# max32660 register map
Vendor: Maxim Integrated; Series: ARMCM4; File version: 1.0
CPU: CM4 r2p1, little endian, MPU, FPU, 3 interrupt priority bits
Registers are 32-bit, read-write, reset 0x0 unless marked. A register's access mark holds for its fields unless they carry their own. Offsets are from the block's base; [hi:lo] are bit positions; {n}, {i} and the like mark numbered series.

## ICC0 — Instruction Cache Controller Registers
Base 0x4002A000
Same registers: ICC1 0x4002F000
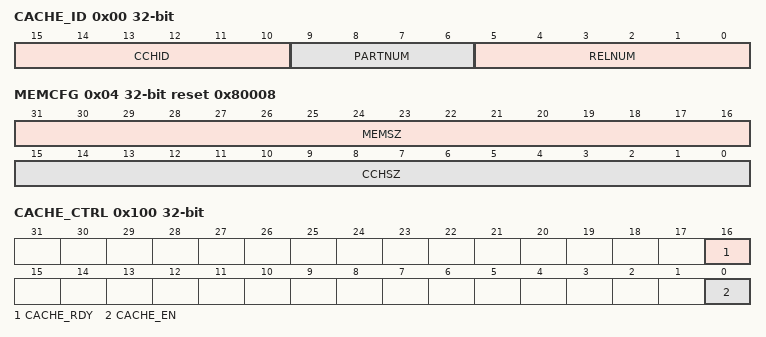
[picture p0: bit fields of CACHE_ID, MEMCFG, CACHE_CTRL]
0x00 CACHE_ID ro
  [15:10] CCHID — Cache ID. This field reflects the value of the C_ID_CACHEID configuration parameter.
  [9:6] PARTNUM — Part Number. This field reflects the value of C_ID_PART_NUMBER configuration parameter.
  [5:0] RELNUM — Release Number. Identifies the RTL release version.
0x04 MEMCFG ro reset 0x80008 — Memory Configuration Register.
  [31:16] MEMSZ — Main Memory Size. Indicates the total size, in units of 128 Kbytes, of code memory accessible to the cache controller.
  [15:0] CCHSZ — Cache Size. Indicates total size in Kbytes of cache.
0x100 CACHE_CTRL — Cache Control and Status Register.
  [16] CACHE_RDY ro — Cache Ready flag. Cleared by hardware when at any time the cache as a whole is invalidated (including a system reset). When this bit is 0, the cache is effectively in bypass mode (instruction fetches will come from main memory or from the line fill buffer). Set by hardware when the invalidate operation is complete and the cache is ready.
    0=notReady; 1=ready
  [0] CACHE_EN — Cache Enable. Controls whether the cache is bypassed or is in use. Changing the state of this bit will cause the instruction cache to be flushed and its contents invalidated.
    0=dis (Cache Bypassed. Instruction data is stored in the line fill buffer but is not written to main cache memory array.); 1=en (Cache Enabled.)
0x700 INVALIDATE — Invalidate All Registers.

## PWRSEQ — Power Sequencer / Low Power Control Register.
Base 0x40006800
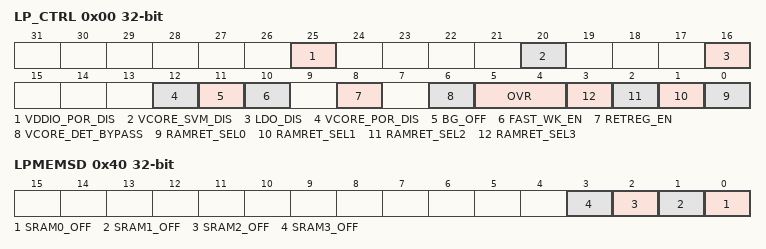
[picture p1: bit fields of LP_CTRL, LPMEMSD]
0x00 LP_CTRL — Low Power Control Register.
  [25] VDDIO_POR_DIS — VDDIO Power-On Reset Monitor Disable. This bit controls the Power-On Reset monitor on VDDIO supply in all operating mods.
    0=en (Enabled.); 1=dis (Disabled.)
  [20] VCORE_SVM_DIS — V CORE Supply Voltage Monitor Disable
    0=en (Enable if Bandgap is ON(default)); 1=dis (Disabled.)
  [16] LDO_DIS — LDO Disable
    0=en (Enable if Bandgap is ON(default)); 1=dis (Disabled.)
  [12] VCORE_POR_DIS — V CORE POR Disable for DEEPSLEEP and BACKUP Mode
    0=dis (Disabled.); 1=en (Enabled.)
  [11] BG_OFF — Band Gap Disable for DEEPSLEEP and BACKUP Mode
    0=on (Bandgap is always ON.); 1=off (Bandgap is OFF in DeepSleep mode(default).)
  [10] FAST_WK_EN — Fast Wake-Up Mode. This bit enables fast wake-up from DeepSleep mode.
    0=dis (Disabled.); 1=en (Enabled.)
  [8] RETREG_EN — Retention Regulator Enable. This bit controls the retention regulator in BACKUP mode.
    0=dis (Disabled.); 1=en (Enabled.)
  [6] VCORE_DET_BYPASS — Bypass V CORE External Supply Detection
    0=enabled; 1=Disable
  [5:4] OVR — Operating Voltage Range
    0=0_9V (0.9V 24MHz); 1=1_0V (1.0V 48MHz); 2=1_1V (1.1V 96MHz)
  [n] RAMRET_SEL{n} (n=0..3) — System RAM {n} Data retention in BACKUP mode.
    0=dis (Disabled.); 1=en (Enabled.)
0x04 LP_WAKEFL — Low Power Mode Wakeup Flags for GPIO0
  [13:0] WAKEST — Wakeup IRQ flags (write ones to clear). One or more of these bits will be set when the corresponding dedicated GPIO pin(s) transition(s) from low to high or high to low. If GPIO wakeup source is selected, using PM.GPIOWKEN register, and the corresponding bit is also selected in LPWKEN register, an interrupt will be gnerated to wake up the CPU from a low power mode.
0x08 LPWK_EN — Low Power I/O Wakeup Enable Register 0. This register enables low power wakeup functionality for GPIO0.
  [13:0] WAKEEN — Enable wakeup. These bits allow wakeup from the corresponding GPIO pin(s) on transition(s) from low to high or high to low when PM.GPIOWKEN is set. Wakeup status is indicated in PPWKST register.
0x40 LPMEMSD — Low Power Memory Shutdown Control.
  [all] fields
    0=Normal Operating Mode; 1=Shutdown Mode
  [n] SRAM{n}_OFF (n=0..3) — System RAM block {n} Shut Down.
